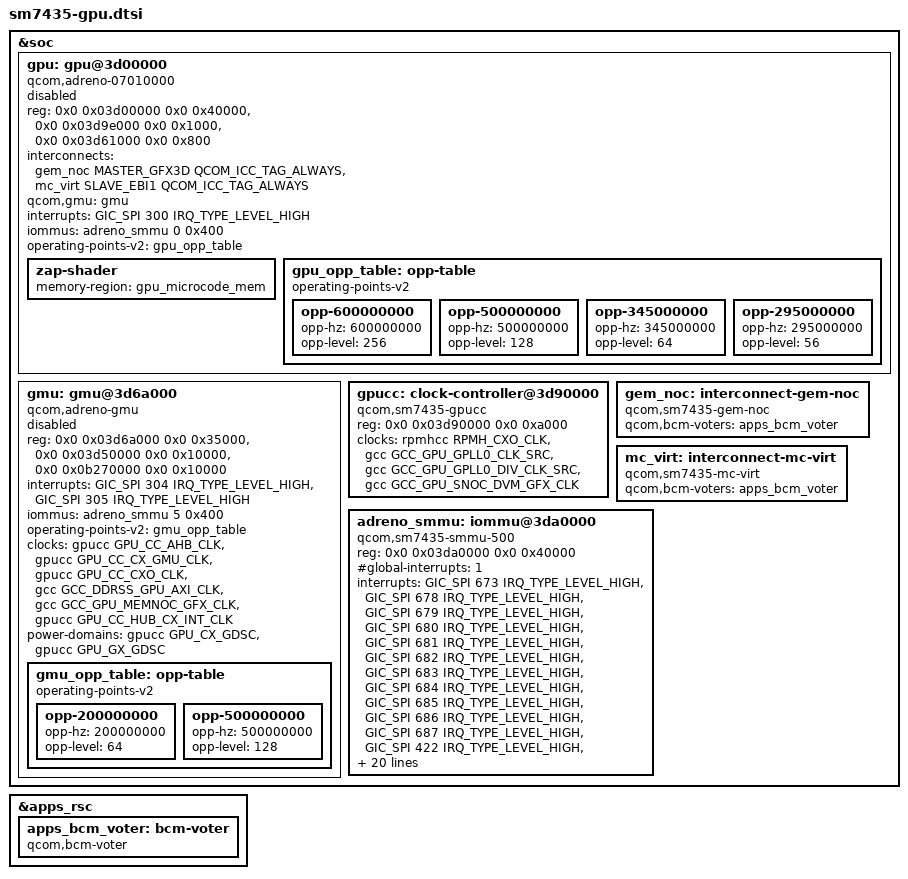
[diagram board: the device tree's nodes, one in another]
// SPDX-License-Identifier: BSD-3-Clause
#include <dt-bindings/interrupt-controller/arm-gic.h>
#include <dt-bindings/interconnect/qcom,icc.h>
#include <dt-bindings/interconnect/qcom,sm7435-rpmh.h>
#include <dt-bindings/clock/qcom,gcc-sm7435.h>
#include <dt-bindings/clock/qcom,sm7435-gpucc.h>
#include <dt-bindings/clock/qcom,rpmh.h>
/*
 * Adreno 710 skeleton. Disabled until gpucc, the interconnect provider
 * and the adreno SMMU exist in sm7435.dtsi. TODO: clocks, power-domains,
 * interconnects, iommus, interrupts, OPP tables (take them from the
 * downstream qcom,kgsl-3d0 node).
 */

&soc {
	gpu: gpu@3d00000 {
		compatible = "qcom,adreno-07010000", "qcom,adreno";
		reg = <0x0 0x03d00000 0x0 0x40000>,
		      <0x0 0x03d9e000 0x0 0x1000>,
		      <0x0 0x03d61000 0x0 0x800>;
		reg-names = "kgsl_3d0_reg_memory", "cx_mem", "cx_dbgc";
		interconnects = <&gem_noc MASTER_GFX3D QCOM_ICC_TAG_ALWAYS
				&mc_virt SLAVE_EBI1 QCOM_ICC_TAG_ALWAYS>;
		interconnect-names = "gfx-mem";
		qcom,gmu = <&gmu>;
		interrupts = <GIC_SPI 300 IRQ_TYPE_LEVEL_HIGH>;
		iommus = <&adreno_smmu 0 0x400>;
		operating-points-v2 = <&gpu_opp_table>;

		status = "disabled";

		zap-shader {
			memory-region = <&gpu_microcode_mem>;
		};

		gpu_opp_table: opp-table {
			compatible = "operating-points-v2";
			/* FIXME: opp-level (rpmh ARC) and opp-peak-kBps per entry */
			opp-600000000 {
				opp-hz = /bits/ 64 <600000000>;
				opp-level = <256>;
			};
			opp-500000000 {
				opp-hz = /bits/ 64 <500000000>;
				opp-level = <128>;
			};
			opp-345000000 {
				opp-hz = /bits/ 64 <345000000>;
				opp-level = <64>;
			};
			opp-295000000 {
				opp-hz = /bits/ 64 <295000000>;
				opp-level = <56>;
			};
		};
	};

	gmu: gmu@3d6a000 {
		compatible = "qcom,adreno-gmu";
		reg = <0x0 0x03d6a000 0x0 0x35000>,
		      <0x0 0x03d50000 0x0 0x10000>,
		      <0x0 0x0b270000 0x0 0x10000>;
		reg-names = "gmu", "rscc", "gmu_pdc";
		interrupts = <GIC_SPI 304 IRQ_TYPE_LEVEL_HIGH>,
			     <GIC_SPI 305 IRQ_TYPE_LEVEL_HIGH>;
		interrupt-names = "hfi", "gmu";
		iommus = <&adreno_smmu 5 0x400>;
		operating-points-v2 = <&gmu_opp_table>;
		clocks = <&gpucc GPU_CC_AHB_CLK>,
			 <&gpucc GPU_CC_CX_GMU_CLK>,
			 <&gpucc GPU_CC_CXO_CLK>,
			 <&gcc GCC_DDRSS_GPU_AXI_CLK>,
			 <&gcc GCC_GPU_MEMNOC_GFX_CLK>,
			 <&gpucc GPU_CC_HUB_CX_INT_CLK>;
		clock-names = "ahb", "gmu", "cxo", "axi", "memnoc", "hub";
		power-domains = <&gpucc GPU_CX_GDSC>, <&gpucc GPU_GX_GDSC>;
		power-domain-names = "cx", "gx";
		status = "disabled";

		gmu_opp_table: opp-table {
			compatible = "operating-points-v2";
			/* FIXME: add opp-level (rpmh ARC) once known */
			opp-200000000 {
				opp-hz = /bits/ 64 <200000000>;
				opp-level = <64>;
			};
			opp-500000000 {
				opp-hz = /bits/ 64 <500000000>;
				opp-level = <128>;
			};
		};
	};
};

&soc {
	gpucc: clock-controller@3d90000 {
		compatible = "qcom,sm7435-gpucc";
		reg = <0x0 0x03d90000 0x0 0xa000>;
		clocks = <&rpmhcc RPMH_CXO_CLK>,
			 <&gcc GCC_GPU_GPLL0_CLK_SRC>,
			 <&gcc GCC_GPU_GPLL0_DIV_CLK_SRC>,
			 <&gcc GCC_GPU_SNOC_DVM_GFX_CLK>;
		#clock-cells = <1>;
		#reset-cells = <1>;
		#power-domain-cells = <1>;
	};
};

&apps_rsc {
	apps_bcm_voter: bcm-voter {
		compatible = "qcom,bcm-voter";
	};
};

&soc {
	gem_noc: interconnect-gem-noc {
		compatible = "qcom,sm7435-gem-noc";
		#interconnect-cells = <2>;
		qcom,bcm-voters = <&apps_bcm_voter>;
	};

	mc_virt: interconnect-mc-virt {
		compatible = "qcom,sm7435-mc-virt";
		#interconnect-cells = <2>;
		qcom,bcm-voters = <&apps_bcm_voter>;
	};
};

&soc {
	adreno_smmu: iommu@3da0000 {
		compatible = "qcom,sm7435-smmu-500", "qcom,adreno-smmu",
			     "qcom,smmu-500", "arm,mmu-500";
		reg = <0x0 0x03da0000 0x0 0x40000>;
		#iommu-cells = <2>;
		#global-interrupts = <1>;
		interrupts = <GIC_SPI 673 IRQ_TYPE_LEVEL_HIGH>,
			     <GIC_SPI 678 IRQ_TYPE_LEVEL_HIGH>,
			     <GIC_SPI 679 IRQ_TYPE_LEVEL_HIGH>,
			     <GIC_SPI 680 IRQ_TYPE_LEVEL_HIGH>,
			     <GIC_SPI 681 IRQ_TYPE_LEVEL_HIGH>,
			     <GIC_SPI 682 IRQ_TYPE_LEVEL_HIGH>,
			     <GIC_SPI 683 IRQ_TYPE_LEVEL_HIGH>,
			     <GIC_SPI 684 IRQ_TYPE_LEVEL_HIGH>,
			     <GIC_SPI 685 IRQ_TYPE_LEVEL_HIGH>,
			     <GIC_SPI 686 IRQ_TYPE_LEVEL_HIGH>,
			     <GIC_SPI 687 IRQ_TYPE_LEVEL_HIGH>,
			     <GIC_SPI 422 IRQ_TYPE_LEVEL_HIGH>,
			     <GIC_SPI 476 IRQ_TYPE_LEVEL_HIGH>,
			     <GIC_SPI 574 IRQ_TYPE_LEVEL_HIGH>,
			     <GIC_SPI 575 IRQ_TYPE_LEVEL_HIGH>,
			     <GIC_SPI 576 IRQ_TYPE_LEVEL_HIGH>,
			     <GIC_SPI 577 IRQ_TYPE_LEVEL_HIGH>,
			     <GIC_SPI 659 IRQ_TYPE_LEVEL_HIGH>,
			     <GIC_SPI 661 IRQ_TYPE_LEVEL_HIGH>,
			     <GIC_SPI 664 IRQ_TYPE_LEVEL_HIGH>,
			     <GIC_SPI 665 IRQ_TYPE_LEVEL_HIGH>,
			     <GIC_SPI 666 IRQ_TYPE_LEVEL_HIGH>,
			     <GIC_SPI 668 IRQ_TYPE_LEVEL_HIGH>;
		clocks = <&gcc GCC_GPU_MEMNOC_GFX_CLK>,
			 <&gcc GCC_GPU_SNOC_DVM_GFX_CLK>,
			 <&gpucc GPU_CC_AHB_CLK>,
			 <&gpucc GPU_CC_HLOS1_VOTE_GPU_SMMU_CLK>,
			 <&gpucc GPU_CC_CX_GMU_CLK>,
			 <&gpucc GPU_CC_HUB_CX_INT_CLK>,
			 <&gpucc GPU_CC_HUB_AON_CLK>;
		clock-names = "gcc_gpu_memnoc_gfx_clk",
			      "gcc_gpu_snoc_dvm_gfx_clk",
			      "gpu_cc_ahb_clk",
			      "gpu_cc_hlos1_vote_gpu_smmu_clk",
			      "gpu_cc_cx_gmu_clk",
			      "gpu_cc_hub_cx_int_clk",
			      "gpu_cc_hub_aon_clk";
		power-domains = <&gpucc GPU_CX_GDSC>;
		dma-coherent;
	};
};
